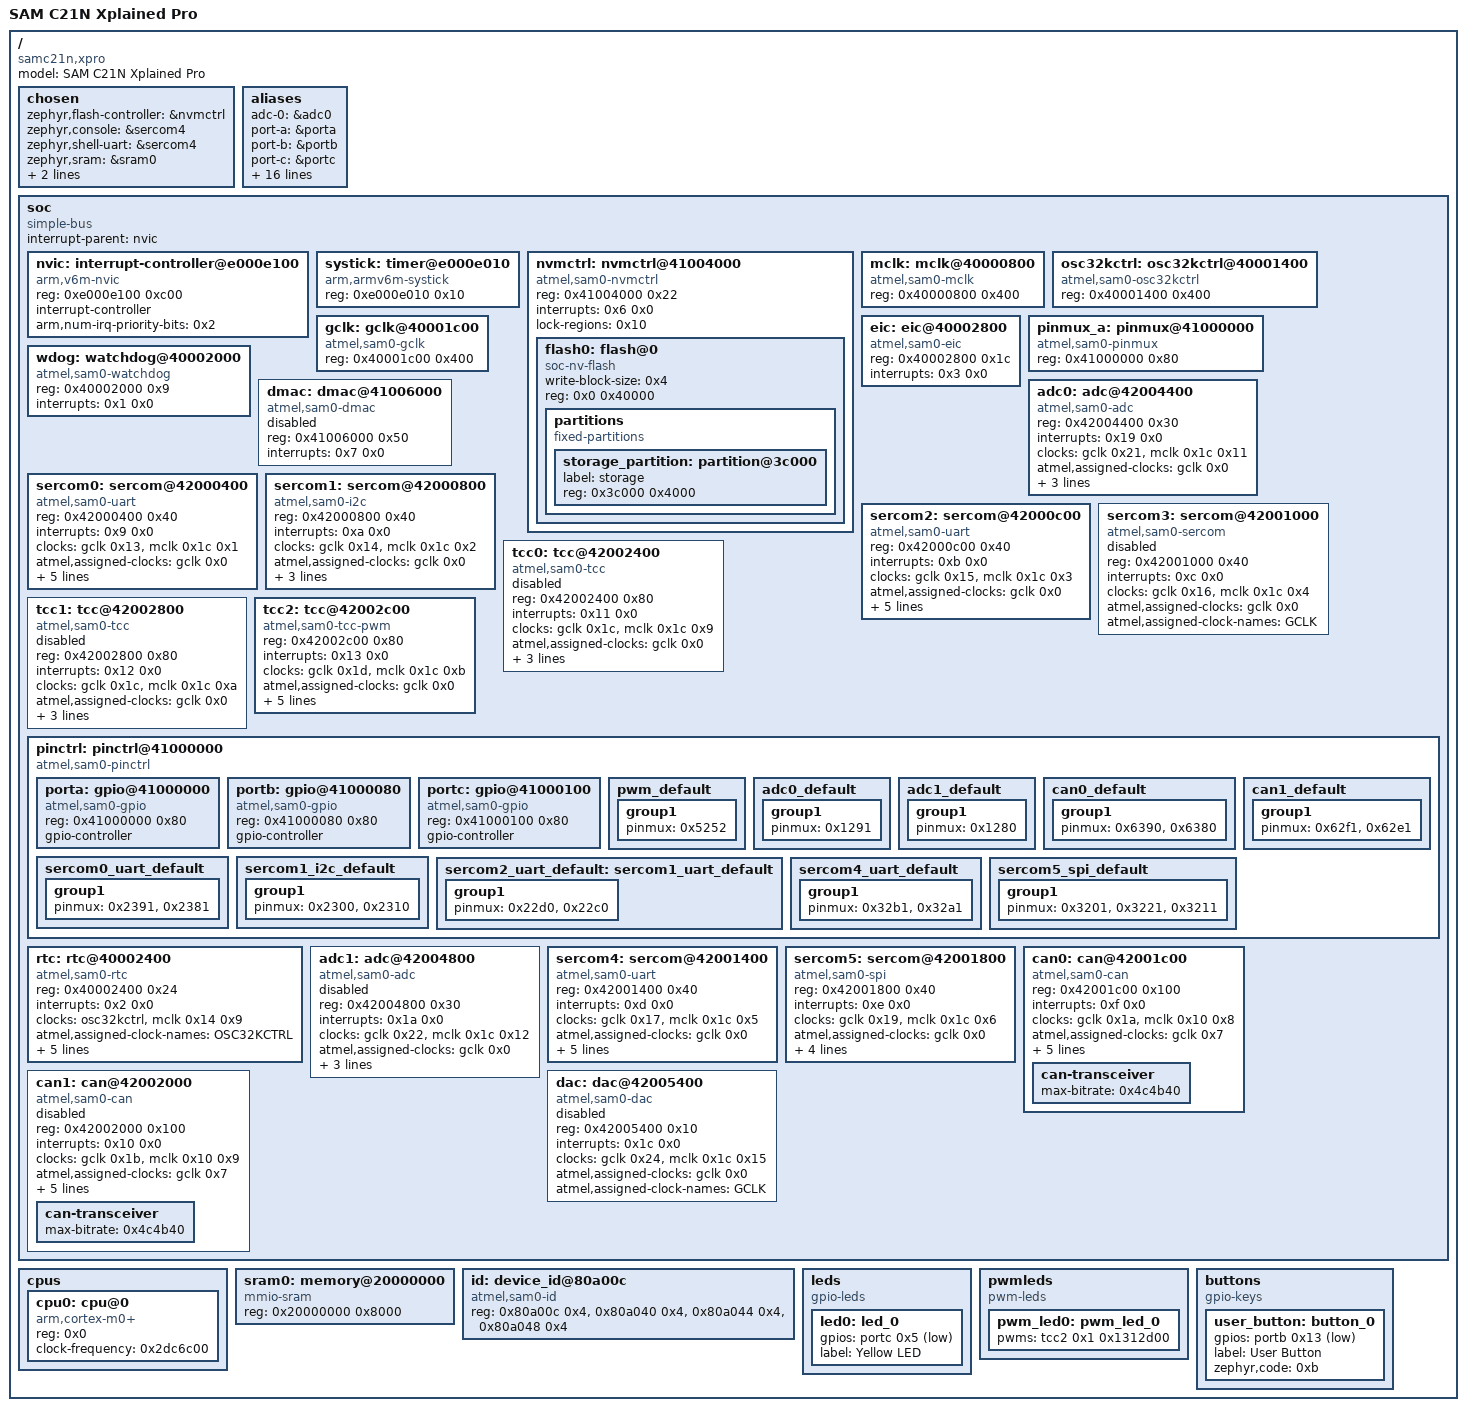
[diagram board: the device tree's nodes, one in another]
/dts-v1/;

/* node '/' defined in zephyr/dts/common/skeleton.dtsi:9 */
/ {
	#address-cells = < 0x1 >;        /* in zephyr/dts/common/skeleton.dtsi:10 */
	#size-cells = < 0x1 >;           /* in zephyr/dts/common/skeleton.dtsi:11 */
	model = "SAM C21N Xplained Pro"; /* in zephyr/boards/atmel/sam0/samc21n_xpro/samc21n_xpro.dts:16 */
	compatible = "samc21n,xpro",
	             "atmel,samc21n18a",
	             "atmel,samc21";     /* in zephyr/boards/atmel/sam0/samc21n_xpro/samc21n_xpro.dts:17 */

	/* node '/chosen' defined in zephyr/dts/common/skeleton.dtsi:13 */
	chosen {
		zephyr,flash-controller = &nvmctrl; /* in zephyr/dts/arm/atmel/samc2x.dtsi:38 */
		zephyr,console = &sercom4;          /* in zephyr/boards/atmel/sam0/samc21n_xpro/samc21n_xpro.dts:20 */
		zephyr,shell-uart = &sercom4;       /* in zephyr/boards/atmel/sam0/samc21n_xpro/samc21n_xpro.dts:21 */
		zephyr,sram = &sram0;               /* in zephyr/boards/atmel/sam0/samc21n_xpro/samc21n_xpro.dts:22 */
		zephyr,flash = &flash0;             /* in zephyr/boards/atmel/sam0/samc21n_xpro/samc21n_xpro.dts:23 */
		zephyr,canbus = &can0;              /* in zephyr/boards/atmel/sam0/samc21n_xpro/samc21n_xpro.dts:24 */
	};

	/* node '/aliases' defined in zephyr/dts/common/skeleton.dtsi:15 */
	aliases {
		adc-0 = &adc0;        /* in zephyr/dts/arm/atmel/samc2x.dtsi:17 */
		port-a = &porta;      /* in zephyr/dts/arm/atmel/samc2x.dtsi:19 */
		port-b = &portb;      /* in zephyr/dts/arm/atmel/samc2x.dtsi:20 */
		port-c = &portc;      /* in zephyr/dts/arm/atmel/samc2x.dtsi:21 */
		rtc = &rtc;           /* in zephyr/dts/arm/atmel/samc2x.dtsi:23 */
		sercom-0 = &sercom0;  /* in zephyr/dts/arm/atmel/samc2x.dtsi:25 */
		sercom-1 = &sercom1;  /* in zephyr/dts/arm/atmel/samc2x.dtsi:26 */
		sercom-2 = &sercom2;  /* in zephyr/dts/arm/atmel/samc2x.dtsi:27 */
		sercom-3 = &sercom3;  /* in zephyr/dts/arm/atmel/samc2x.dtsi:28 */
		tcc-0 = &tcc0;        /* in zephyr/dts/arm/atmel/samc2x.dtsi:30 */
		tcc-1 = &tcc1;        /* in zephyr/dts/arm/atmel/samc2x.dtsi:31 */
		tcc-2 = &tcc2;        /* in zephyr/dts/arm/atmel/samc2x.dtsi:32 */
		watchdog0 = &wdog;    /* in zephyr/dts/arm/atmel/samc2x.dtsi:34 */
		adc-1 = &adc1;        /* in zephyr/dts/arm/atmel/samc21.dtsi:12 */
		sercom-4 = &sercom4;  /* in zephyr/dts/arm/atmel/samc21.dtsi:14 */
		sercom-5 = &sercom5;  /* in zephyr/dts/arm/atmel/samc21.dtsi:15 */
		led0 = &led0;         /* in zephyr/boards/atmel/sam0/samc21n_xpro/samc21n_xpro.dts:29 */
		pwm-led0 = &pwm_led0; /* in zephyr/boards/atmel/sam0/samc21n_xpro/samc21n_xpro.dts:30 */
		sw0 = &user_button;   /* in zephyr/boards/atmel/sam0/samc21n_xpro/samc21n_xpro.dts:31 */
		i2c-0 = &sercom1;     /* in zephyr/boards/atmel/sam0/samc21n_xpro/samc21n_xpro.dts:32 */
	};

	/* node '/soc' defined in zephyr/dts/arm/armv6-m.dtsi:6 */
	soc {
		#address-cells = < 0x1 >;     /* in zephyr/dts/arm/armv6-m.dtsi:7 */
		#size-cells = < 0x1 >;        /* in zephyr/dts/arm/armv6-m.dtsi:8 */
		compatible = "simple-bus";    /* in zephyr/dts/arm/armv6-m.dtsi:9 */
		interrupt-parent = < &nvic >; /* in zephyr/dts/arm/armv6-m.dtsi:10 */
		ranges;                       /* in zephyr/dts/arm/armv6-m.dtsi:11 */

		/* node '/soc/interrupt-controller@e000e100' defined in zephyr/dts/arm/armv6-m.dtsi:13 */
		nvic: interrupt-controller@e000e100 {
			#address-cells = < 0x1 >;            /* in zephyr/dts/arm/armv6-m.dtsi:14 */
			compatible = "arm,v6m-nvic";         /* in zephyr/dts/arm/armv6-m.dtsi:15 */
			reg = < 0xe000e100 0xc00 >;          /* in zephyr/dts/arm/armv6-m.dtsi:16 */
			interrupt-controller;                /* in zephyr/dts/arm/armv6-m.dtsi:17 */
			#interrupt-cells = < 0x2 >;          /* in zephyr/dts/arm/armv6-m.dtsi:18 */
			arm,num-irq-priority-bits = < 0x2 >; /* in zephyr/dts/arm/atmel/samc2x.dtsi:287 */
			phandle = < 0x1 >;                   /* in zephyr/dts/arm/armv6-m.dtsi:10 */
		};

		/* node '/soc/timer@e000e010' defined in zephyr/dts/arm/armv6-m.dtsi:21 */
		systick: timer@e000e010 {
			compatible = "arm,armv6m-systick"; /* in zephyr/dts/arm/armv6-m.dtsi:22 */
			reg = < 0xe000e010 0x10 >;         /* in zephyr/dts/arm/armv6-m.dtsi:23 */
		};

		/* node '/soc/nvmctrl@41004000' defined in zephyr/dts/arm/atmel/samc2x.dtsi:66 */
		nvmctrl: nvmctrl@41004000 {
			compatible = "atmel,sam0-nvmctrl"; /* in zephyr/dts/arm/atmel/samc2x.dtsi:67 */
			reg = < 0x41004000 0x22 >;         /* in zephyr/dts/arm/atmel/samc2x.dtsi:68 */
			interrupts = < 0x6 0x0 >;          /* in zephyr/dts/arm/atmel/samc2x.dtsi:69 */
			#address-cells = < 0x1 >;          /* in zephyr/dts/arm/atmel/samc2x.dtsi:70 */
			#size-cells = < 0x1 >;             /* in zephyr/dts/arm/atmel/samc2x.dtsi:71 */
			lock-regions = < 0x10 >;           /* in zephyr/dts/arm/atmel/samc2x.dtsi:73 */

			/* node '/soc/nvmctrl@41004000/flash@0' defined in zephyr/dts/arm/atmel/samc2x.dtsi:75 */
			flash0: flash@0 {
				compatible = "soc-nv-flash"; /* in zephyr/dts/arm/atmel/samc2x.dtsi:76 */
				write-block-size = < 0x4 >;  /* in zephyr/dts/arm/atmel/samc2x.dtsi:78 */
				reg = < 0x0 0x40000 >;       /* in zephyr/dts/arm/atmel/samx2xx18.dtsi:14 */

				/* node '/soc/nvmctrl@41004000/flash@0/partitions' defined in zephyr/boards/atmel/sam0/samc21n_xpro/samc21n_xpro.dts:153 */
				partitions {
					compatible = "fixed-partitions"; /* in zephyr/boards/atmel/sam0/samc21n_xpro/samc21n_xpro.dts:154 */
					#address-cells = < 0x1 >;        /* in zephyr/boards/atmel/sam0/samc21n_xpro/samc21n_xpro.dts:155 */
					#size-cells = < 0x1 >;           /* in zephyr/boards/atmel/sam0/samc21n_xpro/samc21n_xpro.dts:156 */

					/* node '/soc/nvmctrl@41004000/flash@0/partitions/partition@3c000' defined in zephyr/boards/atmel/sam0/samc21n_xpro/samc21n_xpro.dts:163 */
					storage_partition: partition@3c000 {
						label = "storage";        /* in zephyr/boards/atmel/sam0/samc21n_xpro/samc21n_xpro.dts:164 */
						reg = < 0x3c000 0x4000 >; /* in zephyr/boards/atmel/sam0/samc21n_xpro/samc21n_xpro.dts:165 */
					};
				};
			};
		};

		/* node '/soc/mclk@40000800' defined in zephyr/dts/arm/atmel/samc2x.dtsi:82 */
		mclk: mclk@40000800 {
			compatible = "atmel,sam0-mclk"; /* in zephyr/dts/arm/atmel/samc2x.dtsi:83 */
			reg = < 0x40000800 0x400 >;     /* in zephyr/dts/arm/atmel/samc2x.dtsi:84 */
			#clock-cells = < 0x2 >;         /* in zephyr/dts/arm/atmel/samc2x.dtsi:86 */
			phandle = < 0x3 >;              /* in zephyr/dts/arm/atmel/samc2x.dtsi:135 */
		};

		/* node '/soc/osc32kctrl@40001400' defined in zephyr/dts/arm/atmel/samc2x.dtsi:89 */
		osc32kctrl: osc32kctrl@40001400 {
			compatible = "atmel,sam0-osc32kctrl";  /* in zephyr/dts/arm/atmel/samc2x.dtsi:90 */
			reg = < 0x40001400 0x400 >;            /* in zephyr/dts/arm/atmel/samc2x.dtsi:91 */
			#clock-cells = < 0x0 >;                /* in zephyr/dts/arm/atmel/samc2x.dtsi:92 */
			#atmel,assigned-clock-cells = < 0x1 >; /* in zephyr/dts/arm/atmel/samc2x.dtsi:93 */
			phandle = < 0x9 >;                     /* in zephyr/dts/arm/atmel/samc2x.dtsi:274 */
		};

		/* node '/soc/gclk@40001c00' defined in zephyr/dts/arm/atmel/samc2x.dtsi:96 */
		gclk: gclk@40001c00 {
			compatible = "atmel,sam0-gclk";        /* in zephyr/dts/arm/atmel/samc2x.dtsi:97 */
			reg = < 0x40001c00 0x400 >;            /* in zephyr/dts/arm/atmel/samc2x.dtsi:98 */
			#clock-cells = < 0x1 >;                /* in zephyr/dts/arm/atmel/samc2x.dtsi:100 */
			#atmel,assigned-clock-cells = < 0x1 >; /* in zephyr/dts/arm/atmel/samc2x.dtsi:101 */
			phandle = < 0x2 >;                     /* in zephyr/dts/arm/atmel/samc2x.dtsi:135 */
		};

		/* node '/soc/eic@40002800' defined in zephyr/dts/arm/atmel/samc2x.dtsi:104 */
		eic: eic@40002800 {
			compatible = "atmel,sam0-eic"; /* in zephyr/dts/arm/atmel/samc2x.dtsi:105 */
			reg = < 0x40002800 0x1c >;     /* in zephyr/dts/arm/atmel/samc2x.dtsi:106 */
			interrupts = < 0x3 0x0 >;      /* in zephyr/dts/arm/atmel/samc2x.dtsi:107 */
		};

		/* node '/soc/pinmux@41000000' defined in zephyr/dts/arm/atmel/samc2x.dtsi:110 */
		pinmux_a: pinmux@41000000 {
			compatible = "atmel,sam0-pinmux"; /* in zephyr/dts/arm/atmel/samc2x.dtsi:111 */
			reg = < 0x41000000 0x80 >;        /* in zephyr/dts/arm/atmel/samc2x.dtsi:112 */
		};

		/* node '/soc/watchdog@40002000' defined in zephyr/dts/arm/atmel/samc2x.dtsi:115 */
		wdog: watchdog@40002000 {
			compatible = "atmel,sam0-watchdog"; /* in zephyr/dts/arm/atmel/samc2x.dtsi:116 */
			reg = < 0x40002000 0x9 >;           /* in zephyr/dts/arm/atmel/samc2x.dtsi:117 */
			interrupts = < 0x1 0x0 >;           /* in zephyr/dts/arm/atmel/samc2x.dtsi:118 */
		};

		/* node '/soc/dmac@41006000' defined in zephyr/dts/arm/atmel/samc2x.dtsi:121 */
		dmac: dmac@41006000 {
			compatible = "atmel,sam0-dmac"; /* in zephyr/dts/arm/atmel/samc2x.dtsi:122 */
			reg = < 0x41006000 0x50 >;      /* in zephyr/dts/arm/atmel/samc2x.dtsi:123 */
			interrupts = < 0x7 0x0 >;       /* in zephyr/dts/arm/atmel/samc2x.dtsi:124 */
			status = "disabled";            /* in zephyr/dts/arm/atmel/samc2x.dtsi:125 */
			#dma-cells = < 0x2 >;           /* in zephyr/dts/arm/atmel/samc2x.dtsi:127 */
		};

		/* node '/soc/adc@42004400' defined in zephyr/dts/arm/atmel/samc2x.dtsi:130 */
		adc0: adc@42004400 {
			compatible = "atmel,sam0-adc";         /* in zephyr/dts/arm/atmel/samc2x.dtsi:131 */
			reg = < 0x42004400 0x30 >;             /* in zephyr/dts/arm/atmel/samc2x.dtsi:132 */
			interrupts = < 0x19 0x0 >;             /* in zephyr/dts/arm/atmel/samc2x.dtsi:133 */
			interrupt-names = "resrdy";            /* in zephyr/dts/arm/atmel/samc2x.dtsi:134 */
			clocks = < &gclk 0x21 >,
			         < &mclk 0x1c 0x11 >;          /* in zephyr/dts/arm/atmel/samc2x.dtsi:135 */
			clock-names = "GCLK",
			              "MCLK";                  /* in zephyr/dts/arm/atmel/samc2x.dtsi:136 */
			atmel,assigned-clocks = < &gclk 0x0 >; /* in zephyr/dts/arm/atmel/samc2x.dtsi:137 */
			atmel,assigned-clock-names = "GCLK";   /* in zephyr/dts/arm/atmel/samc2x.dtsi:138 */
			#io-channel-cells = < 0x1 >;           /* in zephyr/dts/arm/atmel/samc2x.dtsi:141 */
			prescaler = < 0x4 >;                   /* in zephyr/dts/arm/atmel/samc2x.dtsi:143 */
			status = "okay";                       /* in zephyr/boards/atmel/sam0/samc21n_xpro/samc21n_xpro.dts:68 */
			pinctrl-0 = < &adc0_default >;         /* in zephyr/boards/atmel/sam0/samc21n_xpro/samc21n_xpro.dts:69 */
			pinctrl-names = "default";             /* in zephyr/boards/atmel/sam0/samc21n_xpro/samc21n_xpro.dts:70 */
		};

		/* node '/soc/sercom@42000400' defined in zephyr/dts/arm/atmel/samc2x.dtsi:146 */
		sercom0: sercom@42000400 {
			reg = < 0x42000400 0x40 >;             /* in zephyr/dts/arm/atmel/samc2x.dtsi:148 */
			interrupts = < 0x9 0x0 >;              /* in zephyr/dts/arm/atmel/samc2x.dtsi:149 */
			clocks = < &gclk 0x13 >,
			         < &mclk 0x1c 0x1 >;           /* in zephyr/dts/arm/atmel/samc2x.dtsi:150 */
			clock-names = "GCLK",
			              "MCLK";                  /* in zephyr/dts/arm/atmel/samc2x.dtsi:151 */
			atmel,assigned-clocks = < &gclk 0x0 >; /* in zephyr/dts/arm/atmel/samc2x.dtsi:152 */
			atmel,assigned-clock-names = "GCLK";   /* in zephyr/dts/arm/atmel/samc2x.dtsi:153 */
			status = "okay";                       /* in zephyr/boards/atmel/sam0/samc21n_xpro/samc21n_xpro.dts:97 */
			compatible = "atmel,sam0-uart";        /* in zephyr/boards/atmel/sam0/samc21n_xpro/samc21n_xpro.dts:98 */
			current-speed = < 0x2580 >;            /* in zephyr/boards/atmel/sam0/samc21n_xpro/samc21n_xpro.dts:99 */
			rxpo = < 0x1 >;                        /* in zephyr/boards/atmel/sam0/samc21n_xpro/samc21n_xpro.dts:100 */
			txpo = < 0x0 >;                        /* in zephyr/boards/atmel/sam0/samc21n_xpro/samc21n_xpro.dts:101 */
			pinctrl-0 = < &sercom0_uart_default >; /* in zephyr/boards/atmel/sam0/samc21n_xpro/samc21n_xpro.dts:103 */
			pinctrl-names = "default";             /* in zephyr/boards/atmel/sam0/samc21n_xpro/samc21n_xpro.dts:104 */
		};

		/* node '/soc/sercom@42000800' defined in zephyr/dts/arm/atmel/samc2x.dtsi:157 */
		sercom1: sercom@42000800 {
			reg = < 0x42000800 0x40 >;             /* in zephyr/dts/arm/atmel/samc2x.dtsi:159 */
			interrupts = < 0xa 0x0 >;              /* in zephyr/dts/arm/atmel/samc2x.dtsi:160 */
			clocks = < &gclk 0x14 >,
			         < &mclk 0x1c 0x2 >;           /* in zephyr/dts/arm/atmel/samc2x.dtsi:161 */
			clock-names = "GCLK",
			              "MCLK";                  /* in zephyr/dts/arm/atmel/samc2x.dtsi:162 */
			atmel,assigned-clocks = < &gclk 0x0 >; /* in zephyr/dts/arm/atmel/samc2x.dtsi:163 */
			atmel,assigned-clock-names = "GCLK";   /* in zephyr/dts/arm/atmel/samc2x.dtsi:164 */
			status = "okay";                       /* in zephyr/boards/atmel/sam0/samc21n_xpro/samc21n_xpro.dts:108 */
			compatible = "atmel,sam0-i2c";         /* in zephyr/boards/atmel/sam0/samc21n_xpro/samc21n_xpro.dts:109 */
			clock-frequency = < 0x61a80 >;         /* in zephyr/boards/atmel/sam0/samc21n_xpro/samc21n_xpro.dts:110 */
			#address-cells = < 0x1 >;              /* in zephyr/boards/atmel/sam0/samc21n_xpro/samc21n_xpro.dts:111 */
			#size-cells = < 0x0 >;                 /* in zephyr/boards/atmel/sam0/samc21n_xpro/samc21n_xpro.dts:112 */
			pinctrl-0 = < &sercom1_i2c_default >;  /* in zephyr/boards/atmel/sam0/samc21n_xpro/samc21n_xpro.dts:114 */
			pinctrl-names = "default";             /* in zephyr/boards/atmel/sam0/samc21n_xpro/samc21n_xpro.dts:115 */
		};

		/* node '/soc/sercom@42000c00' defined in zephyr/dts/arm/atmel/samc2x.dtsi:168 */
		sercom2: sercom@42000c00 {
			reg = < 0x42000c00 0x40 >;             /* in zephyr/dts/arm/atmel/samc2x.dtsi:170 */
			interrupts = < 0xb 0x0 >;              /* in zephyr/dts/arm/atmel/samc2x.dtsi:171 */
			clocks = < &gclk 0x15 >,
			         < &mclk 0x1c 0x3 >;           /* in zephyr/dts/arm/atmel/samc2x.dtsi:172 */
			clock-names = "GCLK",
			              "MCLK";                  /* in zephyr/dts/arm/atmel/samc2x.dtsi:173 */
			atmel,assigned-clocks = < &gclk 0x0 >; /* in zephyr/dts/arm/atmel/samc2x.dtsi:174 */
			atmel,assigned-clock-names = "GCLK";   /* in zephyr/dts/arm/atmel/samc2x.dtsi:175 */
			status = "okay";                       /* in zephyr/boards/atmel/sam0/samc21n_xpro/samc21n_xpro.dts:119 */
			compatible = "atmel,sam0-uart";        /* in zephyr/boards/atmel/sam0/samc21n_xpro/samc21n_xpro.dts:120 */
			current-speed = < 0x1c200 >;           /* in zephyr/boards/atmel/sam0/samc21n_xpro/samc21n_xpro.dts:121 */
			rxpo = < 0x1 >;                        /* in zephyr/boards/atmel/sam0/samc21n_xpro/samc21n_xpro.dts:122 */
			txpo = < 0x0 >;                        /* in zephyr/boards/atmel/sam0/samc21n_xpro/samc21n_xpro.dts:123 */
			pinctrl-0 = < &sercom2_uart_default >; /* in zephyr/boards/atmel/sam0/samc21n_xpro/samc21n_xpro.dts:125 */
			pinctrl-names = "default";             /* in zephyr/boards/atmel/sam0/samc21n_xpro/samc21n_xpro.dts:126 */
		};

		/* node '/soc/sercom@42001000' defined in zephyr/dts/arm/atmel/samc2x.dtsi:179 */
		sercom3: sercom@42001000 {
			compatible = "atmel,sam0-sercom";      /* in zephyr/dts/arm/atmel/samc2x.dtsi:180 */
			reg = < 0x42001000 0x40 >;             /* in zephyr/dts/arm/atmel/samc2x.dtsi:181 */
			interrupts = < 0xc 0x0 >;              /* in zephyr/dts/arm/atmel/samc2x.dtsi:182 */
			clocks = < &gclk 0x16 >,
			         < &mclk 0x1c 0x4 >;           /* in zephyr/dts/arm/atmel/samc2x.dtsi:183 */
			clock-names = "GCLK",
			              "MCLK";                  /* in zephyr/dts/arm/atmel/samc2x.dtsi:184 */
			atmel,assigned-clocks = < &gclk 0x0 >; /* in zephyr/dts/arm/atmel/samc2x.dtsi:185 */
			atmel,assigned-clock-names = "GCLK";   /* in zephyr/dts/arm/atmel/samc2x.dtsi:186 */
			status = "disabled";                   /* in zephyr/dts/arm/atmel/samc2x.dtsi:187 */
		};

		/* node '/soc/tcc@42002400' defined in zephyr/dts/arm/atmel/samc2x.dtsi:190 */
		tcc0: tcc@42002400 {
			compatible = "atmel,sam0-tcc";         /* in zephyr/dts/arm/atmel/samc2x.dtsi:191 */
			reg = < 0x42002400 0x80 >;             /* in zephyr/dts/arm/atmel/samc2x.dtsi:192 */
			interrupts = < 0x11 0x0 >;             /* in zephyr/dts/arm/atmel/samc2x.dtsi:193 */
			clocks = < &gclk 0x1c >,
			         < &mclk 0x1c 0x9 >;           /* in zephyr/dts/arm/atmel/samc2x.dtsi:194 */
			clock-names = "GCLK",
			              "MCLK";                  /* in zephyr/dts/arm/atmel/samc2x.dtsi:195 */
			atmel,assigned-clocks = < &gclk 0x0 >; /* in zephyr/dts/arm/atmel/samc2x.dtsi:196 */
			atmel,assigned-clock-names = "GCLK";   /* in zephyr/dts/arm/atmel/samc2x.dtsi:197 */
			status = "disabled";                   /* in zephyr/dts/arm/atmel/samc2x.dtsi:198 */
			channels = < 0x4 >;                    /* in zephyr/dts/arm/atmel/samc2x.dtsi:200 */
			counter-size = < 0x18 >;               /* in zephyr/dts/arm/atmel/samc2x.dtsi:201 */
		};

		/* node '/soc/tcc@42002800' defined in zephyr/dts/arm/atmel/samc2x.dtsi:204 */
		tcc1: tcc@42002800 {
			compatible = "atmel,sam0-tcc";         /* in zephyr/dts/arm/atmel/samc2x.dtsi:205 */
			reg = < 0x42002800 0x80 >;             /* in zephyr/dts/arm/atmel/samc2x.dtsi:206 */
			interrupts = < 0x12 0x0 >;             /* in zephyr/dts/arm/atmel/samc2x.dtsi:207 */
			clocks = < &gclk 0x1c >,
			         < &mclk 0x1c 0xa >;           /* in zephyr/dts/arm/atmel/samc2x.dtsi:208 */
			clock-names = "GCLK",
			              "MCLK";                  /* in zephyr/dts/arm/atmel/samc2x.dtsi:209 */
			atmel,assigned-clocks = < &gclk 0x0 >; /* in zephyr/dts/arm/atmel/samc2x.dtsi:210 */
			atmel,assigned-clock-names = "GCLK";   /* in zephyr/dts/arm/atmel/samc2x.dtsi:211 */
			status = "disabled";                   /* in zephyr/dts/arm/atmel/samc2x.dtsi:212 */
			channels = < 0x4 >;                    /* in zephyr/dts/arm/atmel/samc2x.dtsi:214 */
			counter-size = < 0x18 >;               /* in zephyr/dts/arm/atmel/samc2x.dtsi:215 */
		};

		/* node '/soc/tcc@42002c00' defined in zephyr/dts/arm/atmel/samc2x.dtsi:218 */
		tcc2: tcc@42002c00 {
			reg = < 0x42002c00 0x80 >;             /* in zephyr/dts/arm/atmel/samc2x.dtsi:220 */
			interrupts = < 0x13 0x0 >;             /* in zephyr/dts/arm/atmel/samc2x.dtsi:221 */
			clocks = < &gclk 0x1d >,
			         < &mclk 0x1c 0xb >;           /* in zephyr/dts/arm/atmel/samc2x.dtsi:222 */
			clock-names = "GCLK",
			              "MCLK";                  /* in zephyr/dts/arm/atmel/samc2x.dtsi:223 */
			atmel,assigned-clocks = < &gclk 0x0 >; /* in zephyr/dts/arm/atmel/samc2x.dtsi:224 */
			atmel,assigned-clock-names = "GCLK";   /* in zephyr/dts/arm/atmel/samc2x.dtsi:225 */
			channels = < 0x2 >;                    /* in zephyr/dts/arm/atmel/samc2x.dtsi:228 */
			counter-size = < 0x10 >;               /* in zephyr/dts/arm/atmel/samc2x.dtsi:229 */
			status = "okay";                       /* in zephyr/boards/atmel/sam0/samc21n_xpro/samc21n_xpro.dts:79 */
			compatible = "atmel,sam0-tcc-pwm";     /* in zephyr/boards/atmel/sam0/samc21n_xpro/samc21n_xpro.dts:80 */
			prescaler = < 0x100 >;                 /* in zephyr/boards/atmel/sam0/samc21n_xpro/samc21n_xpro.dts:81 */
			#pwm-cells = < 0x2 >;                  /* in zephyr/boards/atmel/sam0/samc21n_xpro/samc21n_xpro.dts:82 */
			pinctrl-0 = < &pwm_default >;          /* in zephyr/boards/atmel/sam0/samc21n_xpro/samc21n_xpro.dts:84 */
			pinctrl-names = "default";             /* in zephyr/boards/atmel/sam0/samc21n_xpro/samc21n_xpro.dts:85 */
			phandle = < 0x10 >;                    /* in zephyr/boards/atmel/sam0/samc21n_xpro/samc21n_xpro.dts:48 */
		};

		/* node '/soc/pinctrl@41000000' defined in zephyr/dts/arm/atmel/samc2x.dtsi:232 */
		pinctrl: pinctrl@41000000 {
			compatible = "atmel,sam0-pinctrl";        /* in zephyr/dts/arm/atmel/samc2x.dtsi:233 */
			ranges = < 0x41000000 0x41000000 0x180 >; /* in zephyr/dts/arm/atmel/samc2x.dtsi:234 */
			#address-cells = < 0x1 >;                 /* in zephyr/dts/arm/atmel/samc2x.dtsi:236 */
			#size-cells = < 0x1 >;                    /* in zephyr/dts/arm/atmel/samc2x.dtsi:237 */

			/* node '/soc/pinctrl@41000000/gpio@41000000' defined in zephyr/dts/arm/atmel/samc2x.dtsi:239 */
			porta: gpio@41000000 {
				compatible = "atmel,sam0-gpio"; /* in zephyr/dts/arm/atmel/samc2x.dtsi:240 */
				reg = < 0x41000000 0x80 >;      /* in zephyr/dts/arm/atmel/samc2x.dtsi:241 */
				#atmel,pin-cells = < 0x2 >;     /* in zephyr/dts/arm/atmel/samc2x.dtsi:243 */
				#gpio-cells = < 0x2 >;          /* in zephyr/dts/arm/atmel/samc2x.dtsi:244 */
				gpio-controller;                /* in zephyr/dts/arm/atmel/samc2x.dtsi:246 */
			};

			/* node '/soc/pinctrl@41000000/gpio@41000080' defined in zephyr/dts/arm/atmel/samc2x.dtsi:249 */
			portb: gpio@41000080 {
				compatible = "atmel,sam0-gpio"; /* in zephyr/dts/arm/atmel/samc2x.dtsi:250 */
				reg = < 0x41000080 0x80 >;      /* in zephyr/dts/arm/atmel/samc2x.dtsi:251 */
				#atmel,pin-cells = < 0x2 >;     /* in zephyr/dts/arm/atmel/samc2x.dtsi:253 */
				#gpio-cells = < 0x2 >;          /* in zephyr/dts/arm/atmel/samc2x.dtsi:254 */
				gpio-controller;                /* in zephyr/dts/arm/atmel/samc2x.dtsi:256 */
				phandle = < 0x11 >;             /* in zephyr/boards/atmel/sam0/samc21n_xpro/samc21n_xpro.dts:56 */
			};

			/* node '/soc/pinctrl@41000000/gpio@41000100' defined in zephyr/dts/arm/atmel/samc2x.dtsi:259 */
			portc: gpio@41000100 {
				compatible = "atmel,sam0-gpio"; /* in zephyr/dts/arm/atmel/samc2x.dtsi:260 */
				reg = < 0x41000100 0x80 >;      /* in zephyr/dts/arm/atmel/samc2x.dtsi:261 */
				#atmel,pin-cells = < 0x2 >;     /* in zephyr/dts/arm/atmel/samc2x.dtsi:263 */
				#gpio-cells = < 0x2 >;          /* in zephyr/dts/arm/atmel/samc2x.dtsi:264 */
				gpio-controller;                /* in zephyr/dts/arm/atmel/samc2x.dtsi:266 */
				phandle = < 0xf >;              /* in zephyr/boards/atmel/sam0/samc21n_xpro/samc21n_xpro.dts:39 */
			};

			/* node '/soc/pinctrl@41000000/pwm_default' defined in zephyr/boards/atmel/sam0/samc21n_xpro/samc21n_xpro-pinctrl.dtsi:9 */
			pwm_default: pwm_default {
				phandle = < 0x8 >; /* in zephyr/boards/atmel/sam0/samc21n_xpro/samc21n_xpro.dts:84 */

				/* node '/soc/pinctrl@41000000/pwm_default/group1' defined in zephyr/boards/atmel/sam0/samc21n_xpro/samc21n_xpro-pinctrl.dtsi:10 */
				group1 {
					pinmux = < 0x5252 >; /* in zephyr/boards/atmel/sam0/samc21n_xpro/samc21n_xpro-pinctrl.dtsi:11 */
				};
			};

			/* node '/soc/pinctrl@41000000/adc0_default' defined in zephyr/boards/atmel/sam0/samc21n_xpro/samc21n_xpro-pinctrl.dtsi:15 */
			adc0_default: adc0_default {
				phandle = < 0x4 >; /* in zephyr/boards/atmel/sam0/samc21n_xpro/samc21n_xpro.dts:69 */

				/* node '/soc/pinctrl@41000000/adc0_default/group1' defined in zephyr/boards/atmel/sam0/samc21n_xpro/samc21n_xpro-pinctrl.dtsi:16 */
				group1 {
					pinmux = < 0x1291 >; /* in zephyr/boards/atmel/sam0/samc21n_xpro/samc21n_xpro-pinctrl.dtsi:17 */
				};
			};

			/* node '/soc/pinctrl@41000000/adc1_default' defined in zephyr/boards/atmel/sam0/samc21n_xpro/samc21n_xpro-pinctrl.dtsi:21 */
			adc1_default: adc1_default {
				phandle = < 0xa >; /* in zephyr/boards/atmel/sam0/samc21n_xpro/samc21n_xpro.dts:74 */

				/* node '/soc/pinctrl@41000000/adc1_default/group1' defined in zephyr/boards/atmel/sam0/samc21n_xpro/samc21n_xpro-pinctrl.dtsi:22 */
				group1 {
					pinmux = < 0x1280 >; /* in zephyr/boards/atmel/sam0/samc21n_xpro/samc21n_xpro-pinctrl.dtsi:23 */
				};
			};

			/* node '/soc/pinctrl@41000000/can0_default' defined in zephyr/boards/atmel/sam0/samc21n_xpro/samc21n_xpro-pinctrl.dtsi:27 */
			can0_default: can0_default {
				phandle = < 0xd >; /* in zephyr/boards/atmel/sam0/samc21n_xpro/samc21n_xpro.dts:173 */

				/* node '/soc/pinctrl@41000000/can0_default/group1' defined in zephyr/boards/atmel/sam0/samc21n_xpro/samc21n_xpro-pinctrl.dtsi:28 */
				group1 {
					pinmux = < 0x6390 >,
					         < 0x6380 >; /* in zephyr/boards/atmel/sam0/samc21n_xpro/samc21n_xpro-pinctrl.dtsi:29 */
				};
			};

			/* node '/soc/pinctrl@41000000/can1_default' defined in zephyr/boards/atmel/sam0/samc21n_xpro/samc21n_xpro-pinctrl.dtsi:34 */
			can1_default: can1_default {
				phandle = < 0xe >; /* in zephyr/boards/atmel/sam0/samc21n_xpro/samc21n_xpro.dts:182 */

				/* node '/soc/pinctrl@41000000/can1_default/group1' defined in zephyr/boards/atmel/sam0/samc21n_xpro/samc21n_xpro-pinctrl.dtsi:35 */
				group1 {
					pinmux = < 0x62f1 >,
					         < 0x62e1 >; /* in zephyr/boards/atmel/sam0/samc21n_xpro/samc21n_xpro-pinctrl.dtsi:36 */
				};
			};

			/* node '/soc/pinctrl@41000000/sercom0_uart_default' defined in zephyr/boards/atmel/sam0/samc21n_xpro/samc21n_xpro-pinctrl.dtsi:41 */
			sercom0_uart_default: sercom0_uart_default {
				phandle = < 0x5 >; /* in zephyr/boards/atmel/sam0/samc21n_xpro/samc21n_xpro.dts:103 */

				/* node '/soc/pinctrl@41000000/sercom0_uart_default/group1' defined in zephyr/boards/atmel/sam0/samc21n_xpro/samc21n_xpro-pinctrl.dtsi:42 */
				group1 {
					pinmux = < 0x2391 >,
					         < 0x2381 >; /* in zephyr/boards/atmel/sam0/samc21n_xpro/samc21n_xpro-pinctrl.dtsi:43 */
				};
			};

			/* node '/soc/pinctrl@41000000/sercom1_i2c_default' defined in zephyr/boards/atmel/sam0/samc21n_xpro/samc21n_xpro-pinctrl.dtsi:48 */
			sercom1_i2c_default: sercom1_i2c_default {
				phandle = < 0x6 >; /* in zephyr/boards/atmel/sam0/samc21n_xpro/samc21n_xpro.dts:114 */

				/* node '/soc/pinctrl@41000000/sercom1_i2c_default/group1' defined in zephyr/boards/atmel/sam0/samc21n_xpro/samc21n_xpro-pinctrl.dtsi:49 */
				group1 {
					pinmux = < 0x2300 >,
					         < 0x2310 >; /* in zephyr/boards/atmel/sam0/samc21n_xpro/samc21n_xpro-pinctrl.dtsi:50 */
				};
			};

			/* node '/soc/pinctrl@41000000/sercom1_uart_default' defined in zephyr/boards/atmel/sam0/samc21n_xpro/samc21n_xpro-pinctrl.dtsi:55 */
			sercom2_uart_default: sercom1_uart_default {
				phandle = < 0x7 >; /* in zephyr/boards/atmel/sam0/samc21n_xpro/samc21n_xpro.dts:125 */

				/* node '/soc/pinctrl@41000000/sercom1_uart_default/group1' defined in zephyr/boards/atmel/sam0/samc21n_xpro/samc21n_xpro-pinctrl.dtsi:56 */
				group1 {
					pinmux = < 0x22d0 >,
					         < 0x22c0 >; /* in zephyr/boards/atmel/sam0/samc21n_xpro/samc21n_xpro-pinctrl.dtsi:57 */
				};
			};

			/* node '/soc/pinctrl@41000000/sercom4_uart_default' defined in zephyr/boards/atmel/sam0/samc21n_xpro/samc21n_xpro-pinctrl.dtsi:62 */
			sercom4_uart_default: sercom4_uart_default {
				phandle = < 0xb >; /* in zephyr/boards/atmel/sam0/samc21n_xpro/samc21n_xpro.dts:136 */

				/* node '/soc/pinctrl@41000000/sercom4_uart_default/group1' defined in zephyr/boards/atmel/sam0/samc21n_xpro/samc21n_xpro-pinctrl.dtsi:63 */
				group1 {
					pinmux = < 0x32b1 >,
					         < 0x32a1 >; /* in zephyr/boards/atmel/sam0/samc21n_xpro/samc21n_xpro-pinctrl.dtsi:64 */
				};
			};

			/* node '/soc/pinctrl@41000000/sercom5_spi_default' defined in zephyr/boards/atmel/sam0/samc21n_xpro/samc21n_xpro-pinctrl.dtsi:69 */
			sercom5_spi_default: sercom5_spi_default {
				phandle = < 0xc >; /* in zephyr/boards/atmel/sam0/samc21n_xpro/samc21n_xpro.dts:148 */

				/* node '/soc/pinctrl@41000000/sercom5_spi_default/group1' defined in zephyr/boards/atmel/sam0/samc21n_xpro/samc21n_xpro-pinctrl.dtsi:70 */
				group1 {
					pinmux = < 0x3201 >,
					         < 0x3221 >,
					         < 0x3211 >; /* in zephyr/boards/atmel/sam0/samc21n_xpro/samc21n_xpro-pinctrl.dtsi:71 */
				};
			};
		};

		/* node '/soc/rtc@40002400' defined in zephyr/dts/arm/atmel/samc2x.dtsi:270 */
		rtc: rtc@40002400 {
			compatible = "atmel,sam0-rtc";               /* in zephyr/dts/arm/atmel/samc2x.dtsi:271 */
			reg = < 0x40002400 0x24 >;                   /* in zephyr/dts/arm/atmel/samc2x.dtsi:272 */
			interrupts = < 0x2 0x0 >;                    /* in zephyr/dts/arm/atmel/samc2x.dtsi:273 */
			clocks = < &osc32kctrl >,
			         < &mclk 0x14 0x9 >;                 /* in zephyr/dts/arm/atmel/samc2x.dtsi:274 */
			clock-names = "OSC32KCTRL",
			              "MCLK";                        /* in zephyr/dts/arm/atmel/samc2x.dtsi:275 */
			atmel,assigned-clock-names = "OSC32KCTRL";   /* in zephyr/dts/arm/atmel/samc2x.dtsi:277 */
			alarms-count = < 0x1 >;                      /* in zephyr/dts/arm/atmel/samc2x.dtsi:280 */
			cal-constant = < 0xf0000 >;                  /* in zephyr/dts/arm/atmel/samc2x.dtsi:281 */
			status = "okay";                             /* in zephyr/boards/atmel/sam0/samc21n_xpro/samc21n_xpro.dts:89 */
			counter-mode = "clock";                      /* in zephyr/boards/atmel/sam0/samc21n_xpro/samc21n_xpro.dts:90 */
			prescaler = < 0x400 >;                       /* in zephyr/boards/atmel/sam0/samc21n_xpro/samc21n_xpro.dts:91 */
			atmel,assigned-clocks = < &osc32kctrl 0x4 >; /* in zephyr/boards/atmel/sam0/samc21n_xpro/samc21n_xpro.dts:93 */
		};

		/* node '/soc/adc@42004800' defined in zephyr/dts/arm/atmel/samc21.dtsi:19 */
		adc1: adc@42004800 {
			compatible = "atmel,sam0-adc";         /* in zephyr/dts/arm/atmel/samc21.dtsi:20 */
			reg = < 0x42004800 0x30 >;             /* in zephyr/dts/arm/atmel/samc21.dtsi:21 */
			interrupts = < 0x1a 0x0 >;             /* in zephyr/dts/arm/atmel/samc21.dtsi:22 */
			interrupt-names = "resrdy";            /* in zephyr/dts/arm/atmel/samc21.dtsi:23 */
			clocks = < &gclk 0x22 >,
			         < &mclk 0x1c 0x12 >;          /* in zephyr/dts/arm/atmel/samc21.dtsi:24 */
			clock-names = "GCLK",
			              "MCLK";                  /* in zephyr/dts/arm/atmel/samc21.dtsi:25 */
			atmel,assigned-clocks = < &gclk 0x0 >; /* in zephyr/dts/arm/atmel/samc21.dtsi:26 */
			atmel,assigned-clock-names = "GCLK";   /* in zephyr/dts/arm/atmel/samc21.dtsi:27 */
			status = "disabled";                   /* in zephyr/dts/arm/atmel/samc21.dtsi:28 */
			#io-channel-cells = < 0x1 >;           /* in zephyr/dts/arm/atmel/samc21.dtsi:30 */
			prescaler = < 0x4 >;                   /* in zephyr/dts/arm/atmel/samc21.dtsi:32 */
			pinctrl-0 = < &adc1_default >;         /* in zephyr/boards/atmel/sam0/samc21n_xpro/samc21n_xpro.dts:74 */
			pinctrl-names = "default";             /* in zephyr/boards/atmel/sam0/samc21n_xpro/samc21n_xpro.dts:75 */
		};

		/* node '/soc/sercom@42001400' defined in zephyr/dts/arm/atmel/samc21.dtsi:35 */
		sercom4: sercom@42001400 {
			reg = < 0x42001400 0x40 >;             /* in zephyr/dts/arm/atmel/samc21.dtsi:37 */
			interrupts = < 0xd 0x0 >;              /* in zephyr/dts/arm/atmel/samc21.dtsi:38 */
			clocks = < &gclk 0x17 >,
			         < &mclk 0x1c 0x5 >;           /* in zephyr/dts/arm/atmel/samc21.dtsi:39 */
			clock-names = "GCLK",
			              "MCLK";                  /* in zephyr/dts/arm/atmel/samc21.dtsi:40 */
			atmel,assigned-clocks = < &gclk 0x0 >; /* in zephyr/dts/arm/atmel/samc21.dtsi:41 */
			atmel,assigned-clock-names = "GCLK";   /* in zephyr/dts/arm/atmel/samc21.dtsi:42 */
			status = "okay";                       /* in zephyr/boards/atmel/sam0/samc21n_xpro/samc21n_xpro.dts:130 */
			compatible = "atmel,sam0-uart";        /* in zephyr/boards/atmel/sam0/samc21n_xpro/samc21n_xpro.dts:131 */
			current-speed = < 0x1c200 >;           /* in zephyr/boards/atmel/sam0/samc21n_xpro/samc21n_xpro.dts:132 */
			rxpo = < 0x3 >;                        /* in zephyr/boards/atmel/sam0/samc21n_xpro/samc21n_xpro.dts:133 */
			txpo = < 0x1 >;                        /* in zephyr/boards/atmel/sam0/samc21n_xpro/samc21n_xpro.dts:134 */
			pinctrl-0 = < &sercom4_uart_default >; /* in zephyr/boards/atmel/sam0/samc21n_xpro/samc21n_xpro.dts:136 */
			pinctrl-names = "default";             /* in zephyr/boards/atmel/sam0/samc21n_xpro/samc21n_xpro.dts:137 */
		};

		/* node '/soc/sercom@42001800' defined in zephyr/dts/arm/atmel/samc21.dtsi:46 */
		sercom5: sercom@42001800 {
			reg = < 0x42001800 0x40 >;             /* in zephyr/dts/arm/atmel/samc21.dtsi:48 */
			interrupts = < 0xe 0x0 >;              /* in zephyr/dts/arm/atmel/samc21.dtsi:49 */
			clocks = < &gclk 0x19 >,
			         < &mclk 0x1c 0x6 >;           /* in zephyr/dts/arm/atmel/samc21.dtsi:50 */
			clock-names = "GCLK",
			              "MCLK";                  /* in zephyr/dts/arm/atmel/samc21.dtsi:51 */
			atmel,assigned-clocks = < &gclk 0x0 >; /* in zephyr/dts/arm/atmel/samc21.dtsi:52 */
			atmel,assigned-clock-names = "GCLK";   /* in zephyr/dts/arm/atmel/samc21.dtsi:53 */
			status = "okay";                       /* in zephyr/boards/atmel/sam0/samc21n_xpro/samc21n_xpro.dts:141 */
			compatible = "atmel,sam0-spi";         /* in zephyr/boards/atmel/sam0/samc21n_xpro/samc21n_xpro.dts:142 */
			dipo = < 0x0 >;                        /* in zephyr/boards/atmel/sam0/samc21n_xpro/samc21n_xpro.dts:143 */
			dopo = < 0x2 >;                        /* in zephyr/boards/atmel/sam0/samc21n_xpro/samc21n_xpro.dts:144 */
			#address-cells = < 0x1 >;              /* in zephyr/boards/atmel/sam0/samc21n_xpro/samc21n_xpro.dts:145 */
			#size-cells = < 0x0 >;                 /* in zephyr/boards/atmel/sam0/samc21n_xpro/samc21n_xpro.dts:146 */
			pinctrl-0 = < &sercom5_spi_default >;  /* in zephyr/boards/atmel/sam0/samc21n_xpro/samc21n_xpro.dts:148 */
			pinctrl-names = "default";             /* in zephyr/boards/atmel/sam0/samc21n_xpro/samc21n_xpro.dts:149 */
		};

		/* node '/soc/can@42001c00' defined in zephyr/dts/arm/atmel/samc21.dtsi:57 */
		can0: can@42001c00 {
			compatible = "atmel,sam0-can";                         /* in zephyr/dts/arm/atmel/samc21.dtsi:58 */
			reg = < 0x42001c00 0x100 >;                            /* in zephyr/dts/arm/atmel/samc21.dtsi:59 */
			interrupts = < 0xf 0x0 >;                              /* in zephyr/dts/arm/atmel/samc21.dtsi:60 */
			interrupt-names = "int0";                              /* in zephyr/dts/arm/atmel/samc21.dtsi:61 */
			clocks = < &gclk 0x1a >,
			         < &mclk 0x10 0x8 >;                           /* in zephyr/dts/arm/atmel/samc21.dtsi:62 */
			clock-names = "GCLK",
			              "MCLK";                                  /* in zephyr/dts/arm/atmel/samc21.dtsi:63 */
			atmel,assigned-clocks = < &gclk 0x7 >;                 /* in zephyr/dts/arm/atmel/samc21.dtsi:64 */
			atmel,assigned-clock-names = "GCLK";                   /* in zephyr/dts/arm/atmel/samc21.dtsi:65 */
			bosch,mram-cfg = < 0x0 0x1c 0x8 0x3 0x3 0x0 0x1 0x1 >; /* in zephyr/dts/arm/atmel/samc21.dtsi:68 */
			divider = < 0x1 >;                                     /* in zephyr/dts/arm/atmel/samc21.dtsi:69 */
			status = "okay";                                       /* in zephyr/boards/atmel/sam0/samc21n_xpro/samc21n_xpro.dts:171 */
			pinctrl-0 = < &can0_default >;                         /* in zephyr/boards/atmel/sam0/samc21n_xpro/samc21n_xpro.dts:173 */
			pinctrl-names = "default";                             /* in zephyr/boards/atmel/sam0/samc21n_xpro/samc21n_xpro.dts:174 */

			/* node '/soc/can@42001c00/can-transceiver' defined in zephyr/boards/atmel/sam0/samc21n_xpro/samc21n_xpro.dts:176 */
			can-transceiver {
				max-bitrate = < 0x4c4b40 >; /* in zephyr/boards/atmel/sam0/samc21n_xpro/samc21n_xpro.dts:177 */
			};
		};

		/* node '/soc/can@42002000' defined in zephyr/dts/arm/atmel/samc21.dtsi:72 */
		can1: can@42002000 {
			compatible = "atmel,sam0-can";                         /* in zephyr/dts/arm/atmel/samc21.dtsi:73 */
			reg = < 0x42002000 0x100 >;                            /* in zephyr/dts/arm/atmel/samc21.dtsi:74 */
			interrupts = < 0x10 0x0 >;                             /* in zephyr/dts/arm/atmel/samc21.dtsi:75 */
			interrupt-names = "int0";                              /* in zephyr/dts/arm/atmel/samc21.dtsi:76 */
			clocks = < &gclk 0x1b >,
			         < &mclk 0x10 0x9 >;                           /* in zephyr/dts/arm/atmel/samc21.dtsi:77 */
			clock-names = "GCLK",
			              "MCLK";                                  /* in zephyr/dts/arm/atmel/samc21.dtsi:78 */
			atmel,assigned-clocks = < &gclk 0x7 >;                 /* in zephyr/dts/arm/atmel/samc21.dtsi:79 */
			atmel,assigned-clock-names = "GCLK";                   /* in zephyr/dts/arm/atmel/samc21.dtsi:80 */
			status = "disabled";                                   /* in zephyr/dts/arm/atmel/samc21.dtsi:81 */
			bosch,mram-cfg = < 0x0 0x1c 0x8 0x3 0x3 0x0 0x1 0x1 >; /* in zephyr/dts/arm/atmel/samc21.dtsi:83 */
			divider = < 0x1 >;                                     /* in zephyr/dts/arm/atmel/samc21.dtsi:84 */
			pinctrl-0 = < &can1_default >;                         /* in zephyr/boards/atmel/sam0/samc21n_xpro/samc21n_xpro.dts:182 */
			pinctrl-names = "default";                             /* in zephyr/boards/atmel/sam0/samc21n_xpro/samc21n_xpro.dts:183 */

			/* node '/soc/can@42002000/can-transceiver' defined in zephyr/boards/atmel/sam0/samc21n_xpro/samc21n_xpro.dts:185 */
			can-transceiver {
				max-bitrate = < 0x4c4b40 >; /* in zephyr/boards/atmel/sam0/samc21n_xpro/samc21n_xpro.dts:186 */
			};
		};

		/* node '/soc/dac@42005400' defined in zephyr/dts/arm/atmel/samc21.dtsi:87 */
		dac: dac@42005400 {
			compatible = "atmel,sam0-dac";         /* in zephyr/dts/arm/atmel/samc21.dtsi:88 */
			reg = < 0x42005400 0x10 >;             /* in zephyr/dts/arm/atmel/samc21.dtsi:89 */
			interrupts = < 0x1c 0x0 >;             /* in zephyr/dts/arm/atmel/samc21.dtsi:90 */
			status = "disabled";                   /* in zephyr/dts/arm/atmel/samc21.dtsi:91 */
			#io-channel-cells = < 0x0 >;           /* in zephyr/dts/arm/atmel/samc21.dtsi:93 */
			clocks = < &gclk 0x24 >,
			         < &mclk 0x1c 0x15 >;          /* in zephyr/dts/arm/atmel/samc21.dtsi:94 */
			clock-names = "GCLK",
			              "MCLK";                  /* in zephyr/dts/arm/atmel/samc21.dtsi:95 */
			atmel,assigned-clocks = < &gclk 0x0 >; /* in zephyr/dts/arm/atmel/samc21.dtsi:96 */
			atmel,assigned-clock-names = "GCLK";   /* in zephyr/dts/arm/atmel/samc21.dtsi:97 */
		};
	};

	/* node '/cpus' defined in zephyr/dts/arm/atmel/samc2x.dtsi:41 */
	cpus {
		#address-cells = < 0x1 >; /* in zephyr/dts/arm/atmel/samc2x.dtsi:42 */
		#size-cells = < 0x0 >;    /* in zephyr/dts/arm/atmel/samc2x.dtsi:43 */

		/* node '/cpus/cpu@0' defined in zephyr/dts/arm/atmel/samc2x.dtsi:45 */
		cpu0: cpu@0 {
			compatible = "arm,cortex-m0+";   /* in zephyr/dts/arm/atmel/samc2x.dtsi:46 */
			reg = < 0x0 >;                   /* in zephyr/dts/arm/atmel/samc2x.dtsi:47 */
			device_type = "cpu";             /* in zephyr/dts/arm/atmel/samc2x.dtsi:49 */
			clock-frequency = < 0x2dc6c00 >; /* in zephyr/boards/atmel/sam0/samc21n_xpro/samc21n_xpro.dts:64 */
		};
	};

	/* node '/memory@20000000' defined in zephyr/dts/arm/atmel/samc2x.dtsi:53 */
	sram0: memory@20000000 {
		compatible = "mmio-sram";    /* in zephyr/dts/arm/atmel/samc2x.dtsi:54 */
		reg = < 0x20000000 0x8000 >; /* in zephyr/dts/arm/atmel/samx2xx18.dtsi:10 */
	};

	/* node '/device_id@80a00c' defined in zephyr/dts/arm/atmel/samc2x.dtsi:57 */
	id: device_id@80a00c {
		compatible = "atmel,sam0-id"; /* in zephyr/dts/arm/atmel/samc2x.dtsi:58 */
		reg = < 0x80a00c 0x4 >,
		      < 0x80a040 0x4 >,
		      < 0x80a044 0x4 >,
		      < 0x80a048 0x4 >;       /* in zephyr/dts/arm/atmel/samc2x.dtsi:59 */
	};

	/* node '/leds' defined in zephyr/boards/atmel/sam0/samc21n_xpro/samc21n_xpro.dts:35 */
	leds {
		compatible = "gpio-leds"; /* in zephyr/boards/atmel/sam0/samc21n_xpro/samc21n_xpro.dts:36 */

		/* node '/leds/led_0' defined in zephyr/boards/atmel/sam0/samc21n_xpro/samc21n_xpro.dts:38 */
		led0: led_0 {
			gpios = < &portc 0x5 0x1 >; /* in zephyr/boards/atmel/sam0/samc21n_xpro/samc21n_xpro.dts:39 */
			label = "Yellow LED";       /* in zephyr/boards/atmel/sam0/samc21n_xpro/samc21n_xpro.dts:40 */
		};
	};

	/* node '/pwmleds' defined in zephyr/boards/atmel/sam0/samc21n_xpro/samc21n_xpro.dts:44 */
	pwmleds {
		compatible = "pwm-leds"; /* in zephyr/boards/atmel/sam0/samc21n_xpro/samc21n_xpro.dts:45 */

		/* node '/pwmleds/pwm_led_0' defined in zephyr/boards/atmel/sam0/samc21n_xpro/samc21n_xpro.dts:47 */
		pwm_led0: pwm_led_0 {
			pwms = < &tcc2 0x1 0x1312d00 >; /* in zephyr/boards/atmel/sam0/samc21n_xpro/samc21n_xpro.dts:48 */
		};
	};

	/* node '/buttons' defined in zephyr/boards/atmel/sam0/samc21n_xpro/samc21n_xpro.dts:52 */
	buttons {
		compatible = "gpio-keys"; /* in zephyr/boards/atmel/sam0/samc21n_xpro/samc21n_xpro.dts:53 */

		/* node '/buttons/button_0' defined in zephyr/boards/atmel/sam0/samc21n_xpro/samc21n_xpro.dts:55 */
		user_button: button_0 {
			gpios = < &portb 0x13 0x11 >; /* in zephyr/boards/atmel/sam0/samc21n_xpro/samc21n_xpro.dts:56 */
			label = "User Button";        /* in zephyr/boards/atmel/sam0/samc21n_xpro/samc21n_xpro.dts:57 */
			zephyr,code = < 0xb >;        /* in zephyr/boards/atmel/sam0/samc21n_xpro/samc21n_xpro.dts:58 */
		};
	};
};
